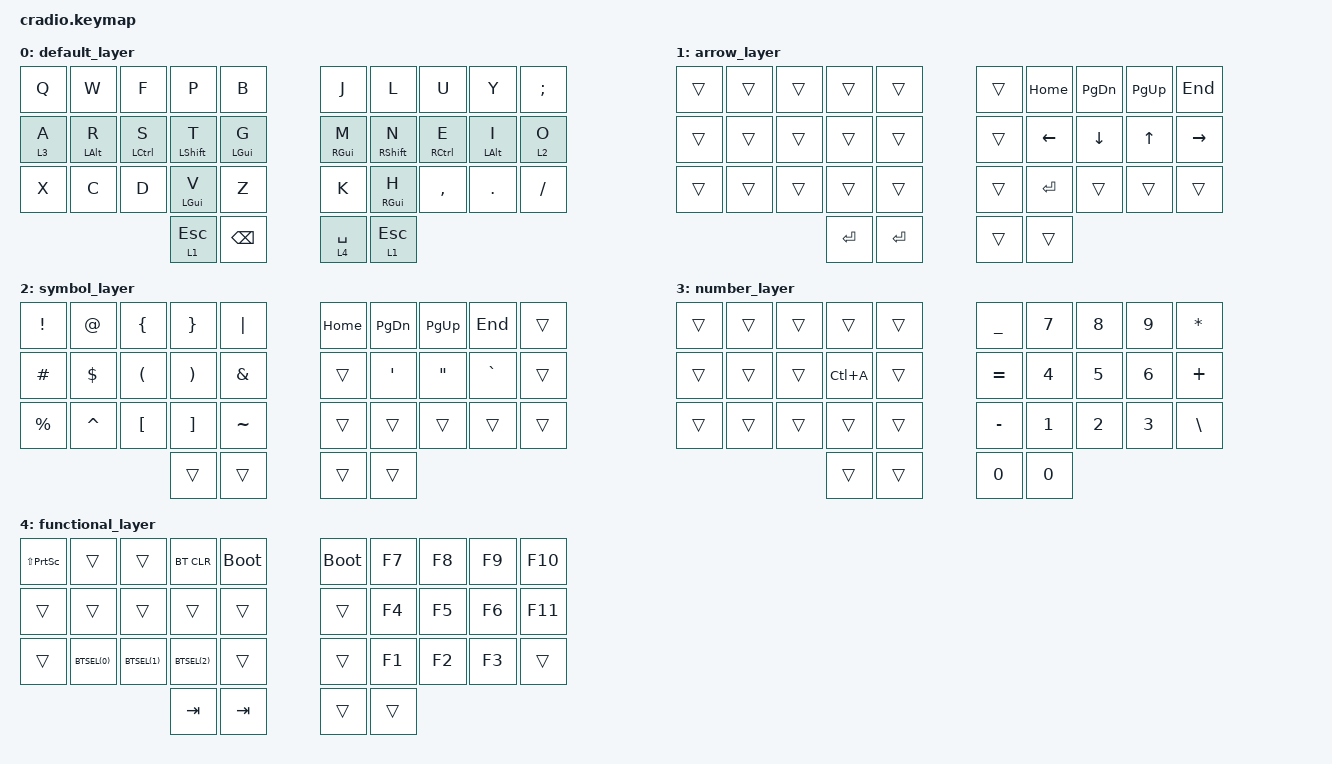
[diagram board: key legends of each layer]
// Copyright (c) 2022 The ZMK Contributors
// SPDX-License-Identifier: MIT

#include <behaviors.dtsi>
#include <dt-bindings/zmk/keys.h>
#include <dt-bindings/zmk/bt.h>

#define BTSEL(n)     &bt BT_SEL n
#define BTCLR        &bt BT_CLR

/ {
    behaviors {
        ht: hold_tap {
            compatible = "zmk,behavior-hold-tap";
            #binding-cells = <2>;
            flavor = "tap-preferred";
            tapping-term-ms = <220>;
            quick-tap-ms = <150>;
            require-prior-idle-ms = <100>;
            bindings = <&kp>, <&kp>;
        };
    };

    keymap {
        compatible = "zmk,keymap";
        default_layer {
            bindings = <
        //╭────────────┬────────────┬────────────┬────────────┬────────────╮   ╭────────────┬────────────┬────────────┬────────────┬────────────╮
        //│    Q       │    W       │    F       │    P       │    B       │   │    J       │    L       │    U       │    Y       │    ;       │
            &kp Q        &kp W        &kp F        &kp P        &kp B            &kp J        &kp L        &kp U        &kp Y        &kp SEMI
        //├────────────┼────────────┼────────────┼────────────┼────────────┤   ├────────────┼────────────┼────────────┼────────────┼────────────┤
        //│    A       │    R       │    S       │    T       │    G       │   │    M       │    N       │    E       │    I       │    O       │
            &lt 3 A      &ht LALT R   &ht LCTRL S  &ht LSHFT T  &ht LGUI G       &ht RGUI M   &ht RSHFT N  &ht RCTRL E  &ht LALT I   &lt 2 O
        //├────────────┼────────────┼────────────┼────────────┼────────────┤   ├────────────┼────────────┼────────────┼────────────┼────────────┤
        //│    X       │    C       │    D       │    V       │    Z       │   │    K       │    H       │    ,       │    .       │    /       │
            &kp X        &kp C        &kp D        &ht LGUI V   &kp Z            &kp K        &ht RGUI H   &kp COMMA    &kp DOT      &kp FSLH
        //╰────────────┴────────────┴────────────┼────────────┼────────────┤   ├────────────┼────────────┼────────────┴────────────┴────────────╯
                                                   &lt 1 ESC    &kp BSPC        &lt 4 SPACE  &lt 1 ESC
        //                                       ╰────────────┴────────────╯   ╰────────────┴────────────╯
            >;
        };

        // layer 1
        arrow_layer {
            bindings = <
        //╭──────────┬──────────┬──────────┬──────────┬──────────╮   ╭──────────┬──────────┬──────────┬──────────┬──────────╮
        //│          │          │          │          │          │   │          │ HOME     │ PAGE DN  │ PAGE UP  │ END      │
            &trans     &trans     &trans    &trans      &trans         &trans    &kp HOME   &kp PG_DN  &kp PG_UP  &kp END 
        //├──────────┼──────────┼──────────┼──────────┼──────────┤   ├──────────┼──────────┼──────────┼──────────┼──────────┤
        //│          │          │          │          │          │   │          │  LEFT    │ DOWN     │ UP       │ RIGHT    │
            &trans     &trans     &trans    &trans      &trans         &trans     &kp LEFT  &kp DOWN   &kp UP     &kp RIGHT
        //├──────────┼──────────┼──────────┼──────────┼──────────┤   ├──────────┼──────────┼──────────┼──────────┼──────────┤
        //│          │          │          │          │          │   │          │  ENTER   │          │          │          │
            &trans     &trans     &trans    &trans      &trans         &trans     &kp ENTER  &trans     &trans     &trans
        //╰──────────┴──────────┴──────────┼──────────┼──────────┤   ├──────────┼──────────┼──────────┴──────────┴──────────╯
                                             &kp ENTER  &kp ENTER      &trans     &trans
        //                                 ╰──────────┴──────────╯   ╰──────────┴──────────╯
            >;
        };

        // layer 2
        symbol_layer {
            bindings = <
        //╭──────────┬──────────┬──────────┬──────────┬──────────╮   ╭──────────┬──────────┬──────────┬──────────┬──────────╮
        //│ !        │  @       │  {       │  }       │  |       │   │ HOME     │ PAGE DN  │ PAGE UP  │ END      │         │
            &kp EXCL   &kp AT     &kp LBRC   &kp RBRC   &kp PIPE      &kp HOME   &kp PG_DN  &kp PG_UP  &kp END    &trans
        //├──────────┼──────────┼──────────┼──────────┼──────────┤   ├──────────┼──────────┼──────────┼──────────┼──────────┤
        //│ #        │  $       │  (       │  )       │  &       │   │          │  '       │ "        │ `        │          │
            &kp HASH   &kp DLLR   &kp LPAR   &kp RPAR   &kp AMPS      &trans      &kp SQT    &kp DQT   &kp GRAVE  &trans
        //├──────────┼──────────┼──────────┼──────────┼──────────┤   ├──────────┼──────────┼──────────┼──────────┼──────────┤
        //│ %        │  ^       │  [       │  ]       │  ~       │   │          │          │          │          │          │
            &kp PRCNT  &kp CARET  &kp LBKT   &kp RBKT   &kp TILDE     &trans     &trans     &trans     &trans     &trans
        //╰──────────┴──────────┴──────────┼──────────┼──────────┤   ├──────────┼──────────┼──────────┴──────────┴──────────╯
                                             &trans     &trans        &trans     &trans
        //                                 ╰──────────┴──────────╯   ╰──────────┴──────────╯
            >;
        };

        // layer 3
        number_layer {
            bindings = <
        //╭──────────┬──────────┬──────────┬──────────┬──────────╮   ╭──────────┬──────────┬──────────┬──────────┬──────────╮
        //│          │          │          │          │          │   │  _       │  7       │  8       │  9       │  *       │
            &trans     &trans     &trans     &trans     &trans         &kp UNDER  &kp N7     &kp N8     &kp N9    &kp ASTRK
        //├──────────┼──────────┼──────────┼──────────┼──────────┤   ├──────────┼──────────┼──────────┼──────────┼──────────┤
        //│          │          │          │          │          │   │  =       │  4       │  5       │  6       │  +       │
            &trans     &trans     &trans     &kp LC(A)  &trans         &kp EQUAL  &kp N4     &kp N5     &kp N6    &kp PLUS
        //├──────────┼──────────┼──────────┼──────────┼──────────┤   ├──────────┼──────────┼──────────┼──────────┼──────────┤
        //│          │          │          │          │          │   │  -       │  1       │  2       │  3       │  \       │
            &trans     &trans     &trans     &trans     &trans         &kp MINUS  &kp N1     &kp N2     &kp N3    &kp BSLH
        //╰──────────┴──────────┴──────────┼──────────┼──────────┤   ├──────────┼──────────┼──────────┴──────────┴──────────╯
                                             &trans     &trans         &kp N0     &kp N0
        //                                 ╰──────────┴──────────╯   ╰──────────┴──────────╯
            >;
        };

        // layer 4
        functional_layer {
            bindings = <
        //╭──────────┬──────────┬──────────┬──────────┬──────────╮   ╭──────────┬──────────┬──────────┬──────────┬──────────╮
        //│ DRUCK    │          │          │          │BOOTLOADER│   │BOOTLOADER│ F7       │ F8       │ F9       │ F10      │
            &kp LS(PSCRN) &trans  &trans     BTCLR    &bootloader    &bootloader &kp F7     &kp F8     &kp F9    &kp F10
        //├──────────┼──────────┼──────────┼──────────┼──────────┤   ├──────────┼──────────┼──────────┼──────────┼──────────┤
        //│          │          │          │          │          │   │          │ F4       │ F5       │ F6       │ F11      │
            &trans     &trans     &trans     &trans     &trans         &trans    &kp F4     &kp F5     &kp F6      &kp F11
        //├──────────┼──────────┼──────────┼──────────┼──────────┤   ├──────────┼──────────┼──────────┼──────────┼──────────┤
        //│          │ PROFILE 0│ PROFILE 1│ PROFILE 2│          │   │          │ F1       │ F2       │ F3       │          │
            &trans     BTSEL(0)   BTSEL(1)   BTSEL(2)   &trans         &trans    &kp F1     &kp F2     &kp F3     &trans
        //╰──────────┴──────────┴──────────┼──────────┼──────────┤   ├──────────┼──────────┼──────────┴──────────┴──────────╯
                                             &kp TAB    &kp TAB        &trans     &trans
        //                                 ╰──────────┴──────────╯   ╰──────────┴──────────╯
            >;
        };
    };
};
